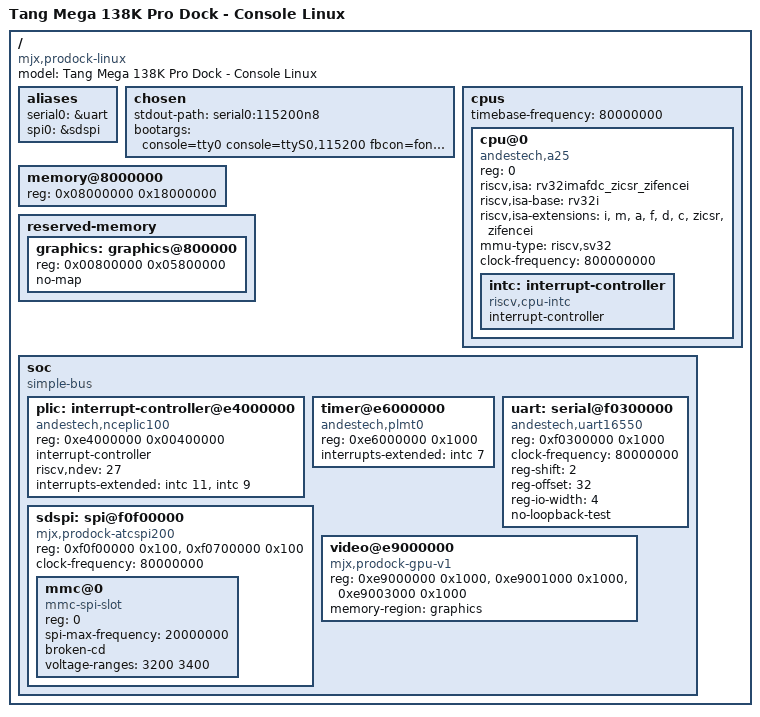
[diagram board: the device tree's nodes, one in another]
// SPDX-License-Identifier: (GPL-2.0-or-later OR MIT)
/dts-v1/;
/ {
	#address-cells = <1>;
	#size-cells = <1>;
	compatible = "mjx,prodock-linux";
	model = "Tang Mega 138K Pro Dock - Console Linux";
	aliases { serial0 = &uart; spi0 = &sdspi; };
	chosen {
		stdout-path = "serial0:115200n8";
		bootargs = "console=tty0 console=ttyS0,115200 fbcon=font:VGA8x16 earlycon=uart8250,mmio32,0xf0300020 loglevel=7 panic=0";
	};
	cpus {
		#address-cells = <1>;
		#size-cells = <0>;
		/* Measured on the Pro Dock: PLMT and APB are 80 MHz. */
		timebase-frequency = <80000000>;
		cpu@0 {
			device_type = "cpu";
			reg = <0>;
			compatible = "andestech,a25", "riscv";
			riscv,isa = "rv32imafdc_zicsr_zifencei";
			riscv,isa-base = "rv32i";
			riscv,isa-extensions = "i", "m", "a", "f", "d", "c", "zicsr", "zifencei";
			mmu-type = "riscv,sv32";
			clock-frequency = <800000000>;
			intc: interrupt-controller {
				compatible = "riscv,cpu-intc";
				interrupt-controller;
				#interrupt-cells = <1>;
				#address-cells = <0>;
			};
		};
	};
	/* Keep all legacy GPU pages/assets outside the Linux allocator. */
	memory@8000000 { device_type = "memory"; reg = <0x08000000 0x18000000>; };
	reserved-memory {
		#address-cells = <1>; #size-cells = <1>; ranges;
		/* OpenSBI adds its own firmware reservations outside Linux RAM. */
		graphics: graphics@800000 { reg = <0x00800000 0x05800000>; no-map; };
	};
	soc {
		compatible = "simple-bus";
		#address-cells = <1>;
		#size-cells = <1>;
		ranges;
		plic: interrupt-controller@e4000000 {
			compatible = "andestech,nceplic100";
			reg = <0xe4000000 0x00400000>;
			interrupt-controller;
			#address-cells = <0>;
			#interrupt-cells = <2>;
			riscv,ndev = <27>;
			interrupts-extended = <&intc 11 &intc 9>;
		};
		timer@e6000000 {
			compatible = "andestech,plmt0";
			reg = <0xe6000000 0x1000>;
			interrupts-extended = <&intc 7>;
		};
		uart: serial@f0300000 {
			compatible = "andestech,uart16550", "ns16550a";
			reg = <0xf0300000 0x1000>;
			clock-frequency = <80000000>;
			reg-shift = <2>;
			reg-offset = <32>;
			reg-io-width = <4>;
			no-loopback-test;
			/* S-mode PLIC/UART delivery is not yet qualified on this core.
			 * Use the upstream 8250 timer path; PLMT interrupts are working. */
		};
		sdspi: spi@f0f00000 {
			compatible = "mjx,prodock-atcspi200";
			reg = <0xf0f00000 0x100>, <0xf0700000 0x100>;
			reg-names = "spi", "gpio";
			clock-frequency = <80000000>;
			#address-cells = <1>; #size-cells = <0>;
			mmc@0 { compatible = "mmc-spi-slot"; reg = <0>;
				spi-max-frequency = <20000000>;
				broken-cd; voltage-ranges = <3200 3400>;
			};
		};
		video@e9000000 {
			compatible = "mjx,prodock-gpu-v1";
			reg = <0xe9000000 0x1000>, <0xe9001000 0x1000>, <0xe9003000 0x1000>;
			reg-names = "display", "accel", "usb-status";
			memory-region = <&graphics>;
		};
	};
};
